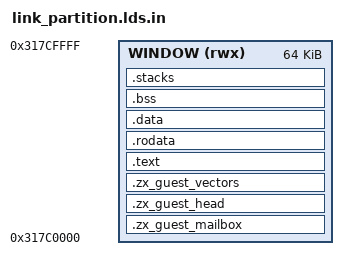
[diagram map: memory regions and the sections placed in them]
/***************************************************************************
 * Copyright (c) 2026 Eclipse ThreadX contributors
 *
 * This program and the accompanying materials are made available under the
 * terms of the MIT License which is available at
 * https://opensource.org/licenses/MIT.
 *
 * AI Disclosure: This file was largely AI-generated by Claude Code (Opus 5).
 * The AI-generated portions may be considered public domain (CC0-1.0)
 * and not subject to the project's licence. The human contributor has
 * reviewed and verified that the code is correct.
 *
 * SPDX-License-Identifier: MIT and CC0-1.0
 **************************************************************************/

/* Link map for a ThreadX guest inside ZoneX partition A, S32Z280-594EVB.
 *
 * WHY THE WINDOW IS IN DATA SRAM AND NOT IN CODE SRAM
 *
 * This board has two memories the RTU reaches at full core speed: 7 MB of
 * code SRAM at 0x79900000 and 512 KB of data SRAM at 0x31780000.  The
 * hypervisor's own text lives in the first and its data in the second.  A
 * PARTITION needs both in ONE CONTIGUOUS WINDOW, for two independent
 * reasons, and data SRAM is the only place that offers it:
 *
 *   * One stage-2 region.  A partition split across two areas needs two
 *     regions and, worse, needs the hypervisor's region budget to grow with
 *     the number of partitions rather than staying fixed.
 *
 *   * objcopy -O binary SPANS ANY GAP between loaded sections and emits it
 *     as padding.  A guest with code at 0x79900000 and data at 0x31780000
 *     produces a blob 1.2 GB long -- the distance between the two areas.
 *     That is not a theoretical hazard: it is the arithmetic.
 *
 * The Cortex-R52 Modules port work chose data SRAM for its module area for
 * exactly this reason, and the code SRAM it left is mapped read-only.
 *
 * AND NOT DRAM2, at 0x31800000, which runs at HALF core speed.  Nothing here
 * would fail if a window were placed there; every timing measurement a later
 * step makes would simply be wrong, quietly, and by a factor nobody would
 * think to look for.  The window below stops well short of it.
 *
 * The layout, the fixed offsets and the ALIGN discipline are identical to the
 * model's script in every other respect; the reasoning for each is written
 * out there rather than repeated here, because the two must not drift and one
 * copy of the argument is easier to keep true than two.
 */

ENTRY(_start)

/* THE WINDOW.  These two numbers are the contract with the hypervisor's own
   linker script and manifest, and the guest declares them in its own image
   header so that a mismatch is REFUSED at boot.

   64 KB, where the model's guest gets 256 KB.  Data SRAM here is 512 KB in
   total and the hypervisor's own data, bss and stack come out of the same
   memory, so the headroom that costs nothing on a 128 MB model is a real
   budget on this board.  The image below links to roughly a third of it.  */

__zx_guest_window_base = 0x317C0000;
__zx_guest_window_size = 0x00010000;

/* Per-mode stacks.  Smaller than the model's for the same reason the window
   is: this is a budget rather than a whole DRAM.  */

__hyp_stack_size__ = 0x0100;    /* unused at EL1, kept so the port links    */
__svc_stack_size__ = 0x0600;
__irq_stack_size__ = 0x0300;
__fiq_stack_size__ = 0x0200;
__abt_stack_size__ = 0x0200;
__und_stack_size__ = 0x0200;
__sys_stack_size__ = 0x0300;

MEMORY
{
    WINDOW (rwx) : ORIGIN = 0x317C0000, LENGTH = 0x00010000
}

SECTIONS
{
    /* +0x00  the mailbox, two granules: LOADED, outside .bss, at the
       window base.  See
       the model's script for why all three of those are forced.  */

    .zx_guest_mailbox : ALIGN(64)
    {
        __zx_guest_mailbox_start = .;
        KEEP(*(.zx_guest_mailbox))
        . = ALIGN(64);
        __zx_guest_mailbox_end = .;
    } > WINDOW

    /* +0x80  the entry branch, then everything executable.  */

    .zx_guest_head : ALIGN(64)
    {
        __zx_guest_code_start = .;
        KEEP(*(.zx_guest_head))
    } > WINDOW

    .zx_guest_vectors : ALIGN(32)
    {
        KEEP(*(.zx_guest_vectors))
    } > WINDOW

    .text :
    {
        KEEP(*(.vectors_el2))
        KEEP(*(.vectors_el1))
        *(.text*)
        *(.glue_7)
        *(.glue_7t)
    } > WINDOW

    .rodata :
    {
        . = ALIGN(4);
        *(.rodata*)
        . = ALIGN(4);
    } > WINDOW

    .data : ALIGN(64)
    {
        __zx_guest_code_end = .;
        __zx_guest_data_start = .;
        __data_start__ = .;
        *(.data*)
        . = ALIGN(4);
    } > WINDOW

    .bss (NOLOAD) :
    {
        . = ALIGN(4);
        __bss_start__ = .;
        *(.bss*)
        *(COMMON)
        . = ALIGN(4);
        __bss_end__ = .;
    } > WINDOW

    .stacks (NOLOAD) :
    {
        . = ALIGN(8);
        . = . + __hyp_stack_size__;
        __hyp_stack_top = .;

        . = ALIGN(8);
        . = . + __svc_stack_size__;
        __svc_stack_top = .;

        . = ALIGN(8);
        . = . + __irq_stack_size__;
        __irq_stack_top = .;

        . = ALIGN(8);
        . = . + __fiq_stack_size__;
        __fiq_stack_top = .;

        . = ALIGN(8);
        . = . + __abt_stack_size__;
        __abt_stack_top = .;

        . = ALIGN(8);
        . = . + __und_stack_size__;
        __und_stack_top = .;

        . = ALIGN(8);
        . = . + __sys_stack_size__;
        __sys_stack_top = .;
    } > WINDOW

    . = ALIGN(8);
    _end = .;
    PROVIDE(end = .);

    __zx_guest_window_end = __zx_guest_window_base + __zx_guest_window_size;
    __zx_guest_data_end   = __zx_guest_window_end;
    __data_end__          = __zx_guest_window_end;
    __code_start__        = __zx_guest_code_start;
    __code_end__          = __zx_guest_code_end;

    ASSERT(__zx_guest_mailbox_start == __zx_guest_window_base,
           "the mailbox is not at the base of the partition window")
    /* TWO granules, and the number is ZX_GD_WINDOW_SIZE in
       examples/common/zx_guest_abi.h.  A linker script cannot include a
       C header, so the constant is restated here and asserted -- which
       is the point: a mailbox that grew past its slot fails the LINK
       rather than moving an entry point the hypervisor computes as a
       compile-time constant.  */
    ASSERT((__zx_guest_mailbox_end - __zx_guest_mailbox_start) == 128,
           "the mailbox is not exactly two granules")
    ASSERT(__zx_guest_code_start == (__zx_guest_window_base + 0x80),
           "the entry branch is not at the offset the hypervisor ERETs to")
    ASSERT(_start >= __zx_guest_code_start,
           "the kernel's reset symbol is outside the guest's code region")
    ASSERT(_start < __zx_guest_code_end,
           "the kernel's reset symbol is outside the guest's code region")

    ASSERT((__zx_guest_code_start & 63) == 0,
           "the guest's code region base is not 64-byte aligned")
    ASSERT((__zx_guest_code_end & 63) == 0,
           "the guest's code region does not end on a granule boundary")
    ASSERT((__zx_guest_data_start & 63) == 0,
           "the guest's writable region base is not 64-byte aligned")

    ASSERT(__zx_guest_mailbox_end <= __bss_start__,
           "the mailbox overlaps .bss, which the boot path zeroes")

    ASSERT(_end <= __zx_guest_window_end,
           "the guest image does not fit its partition window")

    /* And it stays out of the half-speed memory.  Nothing would fail if it
       did not; every timing number a later step produced would simply be
       wrong by a factor nobody would think to look for.  */

    ASSERT(__zx_guest_window_end <= 0x31800000,
           "the partition window reaches into DRAM2, which runs at half core speed")
}
